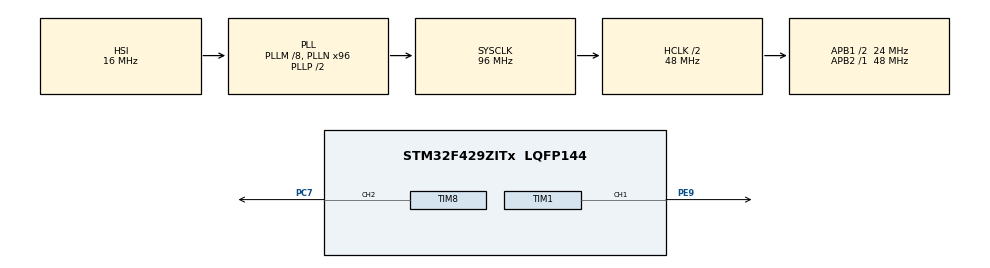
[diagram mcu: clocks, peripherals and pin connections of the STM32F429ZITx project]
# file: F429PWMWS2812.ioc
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Dma.Request0=TIM1_CH1
Dma.Request1=TIM8_CH2
Dma.TIM1_CH1.0.Direction=DMA_MEMORY_TO_PERIPH
Dma.TIM1_CH1.0.FIFOMode=DMA_FIFOMODE_DISABLE
Dma.TIM1_CH1.0.Instance=DMA2_Stream1
Dma.TIM1_CH1.0.MemDataAlignment=DMA_MDATAALIGN_HALFWORD
Dma.TIM1_CH1.0.MemInc=DMA_MINC_ENABLE
Dma.TIM1_CH1.0.Mode=DMA_NORMAL
Dma.TIM1_CH1.0.PeriphDataAlignment=DMA_PDATAALIGN_HALFWORD
Dma.TIM1_CH1.0.PeriphInc=DMA_PINC_DISABLE
Dma.TIM1_CH1.0.Priority=DMA_PRIORITY_MEDIUM
Dma.TIM8_CH2.1.Direction=DMA_MEMORY_TO_PERIPH
Dma.TIM8_CH2.1.FIFOMode=DMA_FIFOMODE_DISABLE
Dma.TIM8_CH2.1.Instance=DMA2_Stream3
Dma.TIM8_CH2.1.MemDataAlignment=DMA_MDATAALIGN_HALFWORD
Dma.TIM8_CH2.1.MemInc=DMA_MINC_ENABLE
Dma.TIM8_CH2.1.Mode=DMA_NORMAL
Dma.TIM8_CH2.1.PeriphDataAlignment=DMA_PDATAALIGN_HALFWORD
Dma.TIM8_CH2.1.PeriphInc=DMA_PINC_DISABLE
Dma.TIM8_CH2.1.Priority=DMA_PRIORITY_MEDIUM
Mcu.Family=STM32F4
Mcu.Name=STM32F429ZITx
Mcu.Package=LQFP144
NVIC.DMA2_Stream1_IRQn=true\:0\:0\:false\:false\:true\:false\:true
NVIC.DMA2_Stream3_IRQn=true\:0\:0\:false\:false\:true\:false\:true
NVIC.PriorityGroup=NVIC_PRIORITYGROUP_4
PA13.Mode=Serial_Wire
PA13.Signal=SYS_JTMS-SWDIO
PA14.Mode=Serial_Wire
PA14.Signal=SYS_JTCK-SWCLK
PC7.Signal=S_TIM8_CH2
PE9.Signal=S_TIM1_CH1
PH0/OSC_IN.Mode=HSE-External-Oscillator
PH0/OSC_IN.Signal=RCC_OSC_IN
PH1/OSC_OUT.Mode=HSE-External-Oscillator
PH1/OSC_OUT.Signal=RCC_OSC_OUT
ProjectManager.HeapSize=0x200
ProjectManager.StackSize=0x400
ProjectManager.TargetToolchain=MDK-ARM V5.27
RCC.48MHZClocksFreq_Value=48000000
RCC.AHBCLKDivider=RCC_SYSCLK_DIV2
RCC.AHBFreq_Value=48000000
RCC.APB1CLKDivider=RCC_HCLK_DIV2
RCC.APB1Freq_Value=24000000
RCC.APB1TimFreq_Value=48000000
RCC.APB2Freq_Value=48000000
RCC.APB2TimFreq_Value=48000000
RCC.CortexFreq_Value=48000000
RCC.HCLKFreq_Value=48000000
RCC.HSE_VALUE=8000000
RCC.HSI_VALUE=16000000
RCC.LSE_VALUE=32768
RCC.PLLM=8
RCC.PLLN=96
RCC.SYSCLKFreq_VALUE=96000000
RCC.SYSCLKSource=RCC_SYSCLKSOURCE_PLLCLK
RCC.VCOOutputFreq_Value=192000000
SH.S_TIM1_CH1.0=TIM1_CH1,PWM Generation1 CH1
SH.S_TIM8_CH2.0=TIM8_CH2,PWM Generation2 CH2
TIM1.Channel-PWM\ Generation1\ CH1=TIM_CHANNEL_1
TIM1.Period=59
TIM8.AutoReloadPreload=TIM_AUTORELOAD_PRELOAD_DISABLE
TIM8.Channel-PWM\ Generation2\ CH2=TIM_CHANNEL_2
TIM8.Period=59
TIM8.TIM_MasterOutputTrigger=TIM_TRGO_RESET
VP_TIM1_VS_ClockSourceINT.Mode=Internal
VP_TIM8_VS_ClockSourceINT.Mode=Internal
board=custom

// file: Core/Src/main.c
/* USER CODE BEGIN Header */
/**
  ******************************************************************************
  * @file           : main.c
  * @brief          : Main program body
  ******************************************************************************
  * @attention
  *
  * <h2><center>&copy; Copyright (c) 2021 STMicroelectronics.
  * All rights reserved.</center></h2>
  *
  * This software component is licensed by ST under BSD 3-Clause license,
  * the "License"; You may not use this file except in compliance with the
  * License. You may obtain a copy of the License at:
  *                        opensource.org/licenses/BSD-3-Clause
  *
  ******************************************************************************
  */
/* USER CODE END Header */
#include "main.h"
#include "dma.h"
#include "tim.h"
#include "gpio.h"

/* USER CODE BEGIN Includes */
#include "ws2812b.h"
/* USER CODE END Includes */

void SystemClock_Config(void);

int main(void)
{

  /* MCU Configuration--------------------------------------------------------*/

  /* Reset of all peripherals, Initializes the Flash interface and the Systick. */
  HAL_Init();

  /* Configure the system clock */
  SystemClock_Config();

  /* Initialize all configured peripherals */
  MX_GPIO_Init();
  MX_DMA_Init();
  MX_TIM8_Init();
  MX_TIM1_Init();
  /* USER CODE BEGIN 2 */
	//__HAL_TIM_SetCompare(&htim8, TIM_CHANNEL_1, 30);
	//__HAL_TIM_SetCompare(&htim1, TIM_CHANNEL_1, 30);
	HAL_TIM_PWM_Start(&htim8, TIM_CHANNEL_2);
	HAL_TIM_PWM_Start(&htim1, TIM_CHANNEL_1);
	WS2812B_Init();
  //HAL_Delay(1000);
  /* USER CODE END 2 */

  /* Infinite loop */
  while (1)
  {

    /* USER CODE BEGIN 3 */
				for(int j = 1; j<12; j++){
			for(int i = 0; i<800; i++){
				WS2812_Process(j);

			}
		}
  }
  /* USER CODE END 3 */
}

void SystemClock_Config(void)
{
  RCC_OscInitTypeDef RCC_OscInitStruct = {0};
  RCC_ClkInitTypeDef RCC_ClkInitStruct = {0};

  /** Configure the main internal regulator output voltage
  */
  __HAL_RCC_PWR_CLK_ENABLE();
  __HAL_PWR_VOLTAGESCALING_CONFIG(PWR_REGULATOR_VOLTAGE_SCALE3);
  /** Initializes the RCC Oscillators according to the specified parameters
  * in the RCC_OscInitTypeDef structure.
  */
  RCC_OscInitStruct.OscillatorType = RCC_OSCILLATORTYPE_HSI;
  RCC_OscInitStruct.HSIState = RCC_HSI_ON;
  RCC_OscInitStruct.HSICalibrationValue = RCC_HSICALIBRATION_DEFAULT;
  RCC_OscInitStruct.PLL.PLLState = RCC_PLL_ON;
  RCC_OscInitStruct.PLL.PLLSource = RCC_PLLSOURCE_HSI;
  RCC_OscInitStruct.PLL.PLLM = 8;
  RCC_OscInitStruct.PLL.PLLN = 96;
  RCC_OscInitStruct.PLL.PLLP = RCC_PLLP_DIV2;
  RCC_OscInitStruct.PLL.PLLQ = 4;
  if (HAL_RCC_OscConfig(&RCC_OscInitStruct) != HAL_OK)
  {
    Error_Handler();
  }
  /** Initializes the CPU, AHB and APB buses clocks
  */
  RCC_ClkInitStruct.ClockType = RCC_CLOCKTYPE_HCLK|RCC_CLOCKTYPE_SYSCLK
                              |RCC_CLOCKTYPE_PCLK1|RCC_CLOCKTYPE_PCLK2;
  RCC_ClkInitStruct.SYSCLKSource = RCC_SYSCLKSOURCE_PLLCLK;
  RCC_ClkInitStruct.AHBCLKDivider = RCC_SYSCLK_DIV2;
  RCC_ClkInitStruct.APB1CLKDivider = RCC_HCLK_DIV2;
  RCC_ClkInitStruct.APB2CLKDivider = RCC_HCLK_DIV1;

  if (HAL_RCC_ClockConfig(&RCC_ClkInitStruct, FLASH_LATENCY_1) != HAL_OK)
  {
    Error_Handler();
  }
}

void Error_Handler(void)
{
  __disable_irq();
  while (1)
  {
  }
}

/************************ (C) COPYRIGHT STMicroelectronics *****END OF FILE****/
